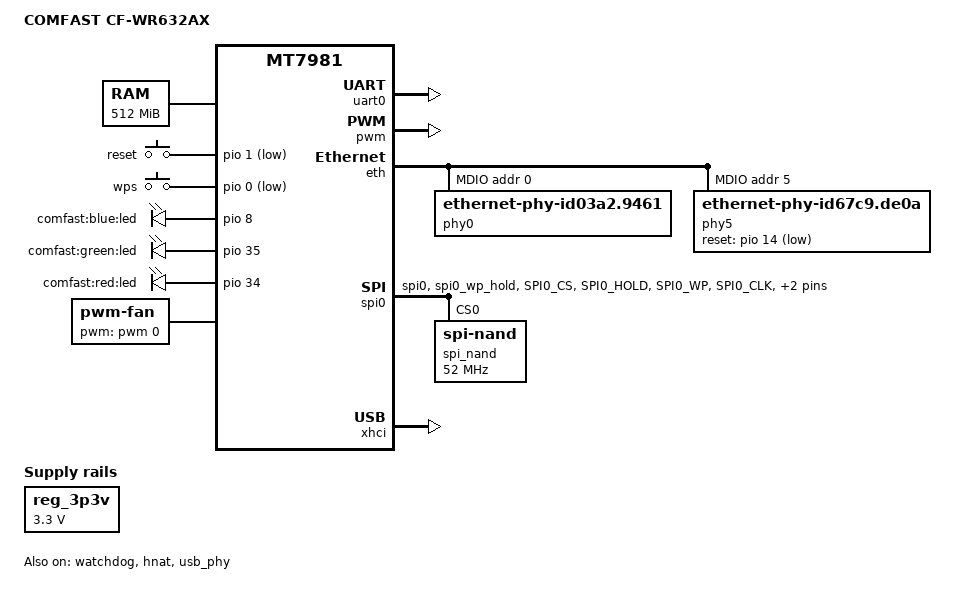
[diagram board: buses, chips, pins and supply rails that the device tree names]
/dts-v1/;
#include "mt7981.dtsi"
/ {
	model = "COMFAST CF-WR632AX";
	compatible = "comfast,cf-wr632ax", "mediatek,mt7981";
	chosen {
		bootargs = "console=ttyS0,115200n1 loglevel=8  \
				earlycon=uart8250,mmio32,0x11002000";
	};

	aliases {
		led-boot = &wan_red;
		led-failsafe = &wan_red;
		led-running = &lan_green;
		led-upgrade = &wan_red;
	};

	memory {
		reg = <0 0x40000000 0 0x20000000>;
	};

	gpio-keys {
			compatible = "gpio-keys";
				reset {
					label = "reset";
					linux,code = <KEY_RESTART>;
					gpios = <&pio 1 GPIO_ACTIVE_LOW>;
				};

				wps {
					label = "wps";
					linux,code = <KEY_WPS_BUTTON>;
					gpios = <&pio 0 GPIO_ACTIVE_LOW>;
				};
	};

	gpio-leds {
			compatible = "gpio-leds";

				wifi_blue: led-0 {
					label = "comfast:blue:led";
					gpios = <&pio 8 GPIO_ACTIVE_HIGH>;
				};

				lan_green: led-1 {
					label = "comfast:green:led";
					gpios = <&pio 35 GPIO_ACTIVE_HIGH>;
				};

				wan_red: led-2 {
					label = "comfast:red:led";
					gpios = <&pio 34 GPIO_ACTIVE_HIGH>;
				};
	};

	nmbm_spim_nand {
		compatible = "generic,nmbm";

		#address-cells = <1>;
		#size-cells = <1>;

		lower-mtd-device = <&spi_nand>;
		forced-create;

		partitions {
			compatible = "fixed-partitions";
			#address-cells = <1>;
			#size-cells = <1>;

			partition@0 {
				label = "BL2";
				reg = <0x00000 0x0100000>;
				read-only;
			};

			partition@100000 {
				label = "u-boot-env";
				reg = <0x0100000 0x0080000>;
			};

			partition@180000 {
				label = "Factory";
				reg = <0x180000 0x0200000>;
			};

			partition@380000 {
				label = "FIP";
				reg = <0x380000 0x0200000>;
			};

			partition@580000 {
				label = "ubi";
				reg = <0x580000 0x4000000>;
			};
		};
	};

	fan: pwm-fan {
		compatible = "pwm-fan";
		#cooling-cells = <2>;
		/* cooling level (0, 1, 2) - pwm inverted */
		//cooling-levels = <255 96 0>;
		cooling-levels = <0 26 51 77 102 128 153 179 204 230 255>;
		pwms = <&pwm 0 10000>;
		status = "okay";
	};
	
	reg_3p3v: regulator-3p3v {
		compatible = "regulator-fixed";
		regulator-name = "fixed-3.3V";
		regulator-min-microvolt = <3300000>;
		regulator-max-microvolt = <3300000>;
		regulator-boot-on;
		regulator-always-on;
	};
};

&uart0 {
	status = "okay";
};

&pwm {
	pinctrl-names = "default";
	pinctrl-0 = <&pwm_pins>;

	status = "okay";
};

&watchdog {
	status = "okay";
};

&eth {
		status = "okay";

		gmac0: mac@0 {
			compatible = "mediatek,eth-mac";
			reg = <0>;
			phy-mode = "2500base-x";

			fixed-link {
					speed = <2500>;
					full-duplex;
					pause;
			};
        };

    	gmac1: mac@1 {
			compatible = "mediatek,eth-mac";
			reg = <1>;
			phy-mode = "gmii";
			phy-handle = <&phy0>;
		};

		mdio: mdio-bus {
			#address-cells = <1>;
			#size-cells = <0>;

			phy0: ethernet-phy@0 {
				compatible = "ethernet-phy-id03a2.9461";
				reg = <0>;
				phy-mode = "gmii";
				nvmem-cells = <&phy_calibration>;
				nvmem-cell-names = "phy-cal-data";
			};
			
			phy5: phy@5 {
				compatible = "ethernet-phy-id67c9.de0a";
				reg = <5>;
				reset-gpios = <&pio 14 1>;
				reset-assert-us = <600>;
				reset-deassert-us = <20000>;
				phy-mode = "2500base-x";
			};
		};
};

&hnat {
	mtketh-wan = "eth0";
	mtketh-lan = "eth1";
	mtketh-max-gmac = <2>;
	status = "okay";
};

&spi0 {
	pinctrl-names = "default";
	pinctrl-0 = <&spi0_flash_pins>;
	status = "okay";

	spi_nand: flash@0 {
		#address-cells = <1>;
		#size-cells = <1>;
		compatible = "spi-nand";
		reg = <0>;
		spi-max-frequency = <52000000>;

		spi-cal-enable;
		spi-cal-mode = "read-data";
		spi-cal-datalen = <7>;
		spi-cal-data = /bits/ 8 <0x53 0x50 0x49 0x4E 0x41 0x4E 0x44>;
		spi-cal-addrlen = <5>;
		spi-cal-addr = /bits/ 32 <0x0 0x0 0x0 0x0 0x0>;

		spi-tx-bus-width = <4>;
		spi-rx-bus-width = <4>;
		mediatek,nmbm;
		mediatek,bmt-max-ratio = <1>;
		mediatek,bmt-max-reserved-blocks = <64>;
	};
};

&pio {
	spi0_flash_pins: spi0-pins {
		mux {
			function = "spi";
			groups = "spi0", "spi0_wp_hold";
		};

		conf-pu {
			pins = "SPI0_CS", "SPI0_HOLD", "SPI0_WP";
			drive-strength = <8>;
			bias-pull-up = <103>;
		};

		conf-pd {
			pins = "SPI0_CLK", "SPI0_MOSI", "SPI0_MISO";
			drive-strength = <8>;
			bias-pull-down = <103>;
		};
	};
	
	pwm0_pin: pwm0-pin-g0 {
			mux {
					function = "pwm";
					groups = "pwm0_0";
			};
	};

	pwm1_pin: pwm1-pin-g0 {
			mux {
					function = "pwm";
					groups = "pwm1_0";
			};
	};

	pwm2_pin: pwm2-pin {
			mux {
					function = "pwm";
					groups = "pwm2";
			};
	};
};

&xhci {
 	vusb33-supply = <&reg_3p3v>;
	status = "okay";
};

&usb_phy {
	status = "okay";
};
